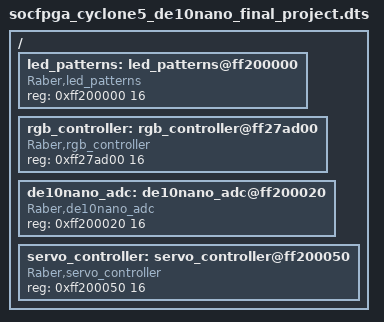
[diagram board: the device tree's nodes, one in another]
#include "socfpga_cyclone5_de10nano.dtsi"

/{
    led_patterns: led_patterns@ff200000 {
        compatible = "Raber,led_patterns";
        reg = <0xff200000 16>;
    };
    rgb_controller: rgb_controller@ff27ad00 {
        compatible = "Raber,rgb_controller";
        reg = <0xff27ad00 16>;
    };
    de10nano_adc: de10nano_adc@ff200020 {
        compatible = "Raber,de10nano_adc";
        reg = <0xff200020 16>;
    };
    servo_controller: servo_controller@ff200050 {
        compatible = "Raber,servo_controller";
        reg = <0xff200050 16>;
    };
};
